VERSION "Infotainment_CAN_v1.0"

NS_ :

BS_:

BU_: VAL_SCENARIO_CTRL IVI CLU CGW TMU VOICE_ASSIST DATC HUD AMP

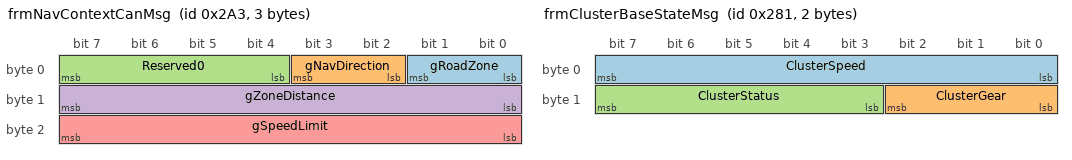
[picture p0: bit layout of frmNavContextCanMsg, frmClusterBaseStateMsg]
BO_ 675 frmNavContextCanMsg: 3 VAL_SCENARIO_CTRL
 SG_ gRoadZone : 0|2@1+ (1,0) [0|3] ""  IVI
 SG_ gNavDirection : 2|2@1+ (1,0) [0|3] ""  IVI
 SG_ Reserved0 : 4|4@1+ (1,0) [0|0] "" Vector__XXX
 SG_ gZoneDistance : 8|8@1+ (1,0) [0|255] "m"  IVI
 SG_ gSpeedLimit : 16|8@1+ (1,0) [0|255] "km/h"  IVI

BO_ 640 frmClusterWarningMsg: 1 IVI
 SG_ WarningTextCode : 0|8@1+ (1,0) [0|255] ""  CLU

BO_ 641 frmClusterBaseStateMsg: 2 IVI
 SG_ ClusterSpeed : 0|8@1+ (1,0) [0|255] "km/h"  CLU
 SG_ ClusterGear : 8|3@1+ (1,0) [0|7] ""  CLU
 SG_ ClusterStatus : 11|5@1+ (1,0) [0|31] ""  CLU

BO_ 642 frmNaviGuideStateMsg: 1 IVI
 SG_ GuideLaneState : 0|2@1+ (1,0) [0|3] ""  IVI
 SG_ GuideConfidence : 2|6@1+ (1,0) [0|63] ""  IVI

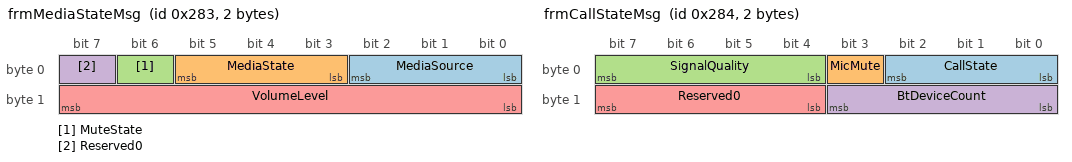
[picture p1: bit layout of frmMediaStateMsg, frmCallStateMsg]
BO_ 643 frmMediaStateMsg: 2 IVI
 SG_ MediaSource : 0|3@1+ (1,0) [0|7] ""  CLU
 SG_ MediaState : 3|3@1+ (1,0) [0|7] ""  CLU
 SG_ MuteState : 6|1@1+ (1,0) [0|1] ""  CLU
 SG_ Reserved0 : 7|1@1+ (1,0) [0|0] "" Vector__XXX
 SG_ VolumeLevel : 8|8@1+ (1,0) [0|100] "%"  CLU

BO_ 644 frmCallStateMsg: 2 IVI
 SG_ CallState : 0|3@1+ (1,0) [0|7] ""  CLU
 SG_ MicMute : 3|1@1+ (1,0) [0|1] ""  CLU
 SG_ SignalQuality : 4|4@1+ (1,0) [0|15] ""  CLU
 SG_ BtDeviceCount : 8|4@1+ (1,0) [0|15] ""  CLU
 SG_ Reserved0 : 12|4@1+ (1,0) [0|0] "" Vector__XXX

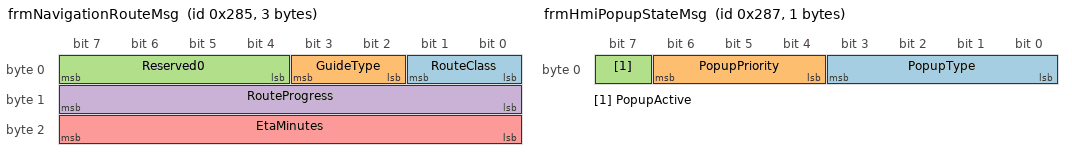
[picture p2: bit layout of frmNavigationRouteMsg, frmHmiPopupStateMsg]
BO_ 645 frmNavigationRouteMsg: 3 IVI
 SG_ RouteClass : 0|2@1+ (1,0) [0|3] ""  IVI
 SG_ GuideType : 2|2@1+ (1,0) [0|3] ""  IVI
 SG_ Reserved0 : 4|4@1+ (1,0) [0|0] "" Vector__XXX
 SG_ RouteProgress : 8|8@1+ (1,0) [0|100] "%"  IVI
 SG_ EtaMinutes : 16|8@1+ (1,0) [0|255] "min"  IVI

BO_ 646 frmClusterThemeMsg: 1 IVI
 SG_ ThemeMode : 0|3@1+ (1,0) [0|7] ""  CLU
 SG_ ClusterBrightness : 3|5@1+ (1,0) [0|31] ""  CLU

BO_ 647 frmHmiPopupStateMsg: 1 IVI
 SG_ PopupType : 0|4@1+ (1,0) [0|15] ""  CLU
 SG_ PopupPriority : 4|3@1+ (1,0) [0|7] ""  CLU
 SG_ PopupActive : 7|1@1+ (1,0) [0|1] ""  CLU

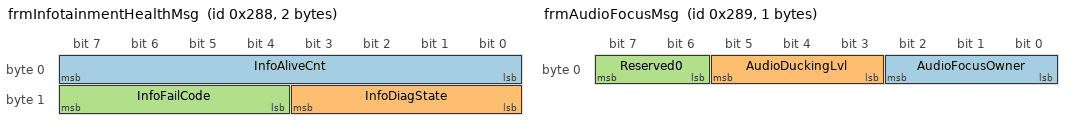
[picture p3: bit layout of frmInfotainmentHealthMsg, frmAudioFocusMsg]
BO_ 648 frmInfotainmentHealthMsg: 2 IVI
 SG_ InfoAliveCnt : 0|8@1+ (1,0) [0|255] ""  VAL_SCENARIO_CTRL,CGW
 SG_ InfoDiagState : 8|4@1+ (1,0) [0|15] ""  VAL_SCENARIO_CTRL,CGW
 SG_ InfoFailCode : 12|4@1+ (1,0) [0|15] ""  VAL_SCENARIO_CTRL,CGW

BO_ 649 frmAudioFocusMsg: 1 IVI
 SG_ AudioFocusOwner : 0|3@1+ (1,0) [0|7] ""  CLU
 SG_ AudioDuckingLvl : 3|3@1+ (1,0) [0|7] ""  CLU
 SG_ Reserved0 : 6|2@1+ (1,0) [0|0] "" Vector__XXX

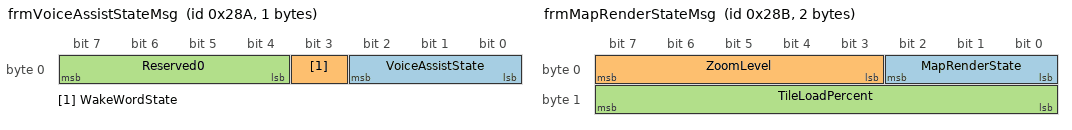
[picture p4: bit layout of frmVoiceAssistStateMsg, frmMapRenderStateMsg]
BO_ 650 frmVoiceAssistStateMsg: 1 VOICE_ASSIST
 SG_ VoiceAssistState : 0|3@1+ (1,0) [0|7] ""  CLU
 SG_ WakeWordState : 3|1@1+ (1,0) [0|1] ""  CLU
 SG_ Reserved0 : 4|4@1+ (1,0) [0|0] "" Vector__XXX

BO_ 651 frmMapRenderStateMsg: 2 IVI
 SG_ MapRenderState : 0|3@1+ (1,0) [0|7] ""  IVI
 SG_ ZoomLevel : 3|5@1+ (1,0) [0|31] ""  IVI
 SG_ TileLoadPercent : 8|8@1+ (1,0) [0|100] "%"  IVI

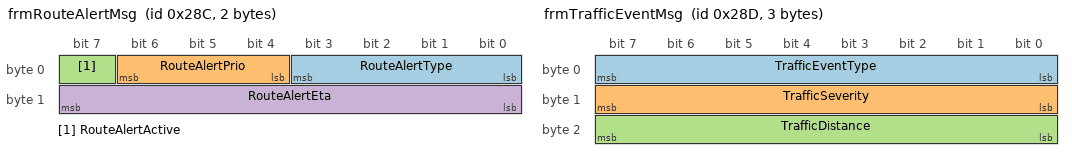
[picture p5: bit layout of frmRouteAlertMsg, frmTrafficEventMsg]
BO_ 652 frmRouteAlertMsg: 2 IVI
 SG_ RouteAlertType : 0|4@1+ (1,0) [0|15] ""  IVI
 SG_ RouteAlertPrio : 4|3@1+ (1,0) [0|7] ""  IVI
 SG_ RouteAlertActive : 7|1@1+ (1,0) [0|1] ""  IVI
 SG_ RouteAlertEta : 8|8@1+ (1,0) [0|255] "s"  IVI

BO_ 653 frmTrafficEventMsg: 3 IVI
 SG_ TrafficEventType : 0|8@1+ (1,0) [0|255] ""  IVI
 SG_ TrafficSeverity : 8|8@1+ (1,0) [0|255] ""  IVI
 SG_ TrafficDistance : 16|8@1+ (1,0) [0|255] "m"  IVI

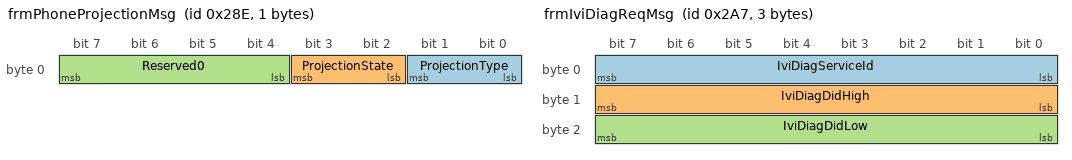
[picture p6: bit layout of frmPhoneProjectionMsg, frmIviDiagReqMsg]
BO_ 654 frmPhoneProjectionMsg: 1 IVI
 SG_ ProjectionType : 0|2@1+ (1,0) [0|3] ""  CLU
 SG_ ProjectionState : 2|2@1+ (1,0) [0|3] ""  CLU
 SG_ Reserved0 : 4|4@1+ (1,0) [0|0] "" Vector__XXX

BO_ 655 frmClusterNotifMsg: 2 IVI
 SG_ ClusterNotifType : 0|8@1+ (1,0) [0|255] ""  CLU
 SG_ ClusterNotifArg : 8|8@1+ (1,0) [0|255] ""  CLU

BO_ 679 frmIviDiagReqMsg: 3 VAL_SCENARIO_CTRL
 SG_ IviDiagServiceId : 0|8@1+ (1,0) [0|255] ""  IVI
 SG_ IviDiagDidHigh : 8|8@1+ (1,0) [0|255] ""  IVI
 SG_ IviDiagDidLow : 16|8@1+ (1,0) [0|255] ""  IVI

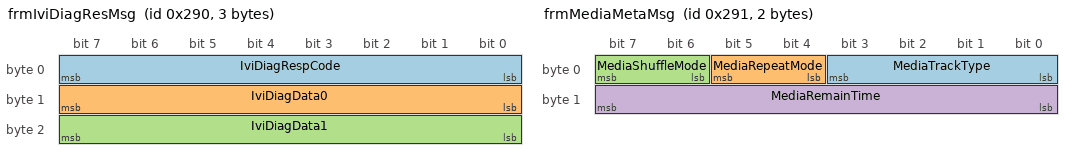
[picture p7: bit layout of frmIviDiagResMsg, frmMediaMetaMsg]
BO_ 656 frmIviDiagResMsg: 3 IVI
 SG_ IviDiagRespCode : 0|8@1+ (1,0) [0|255] ""  VAL_SCENARIO_CTRL
 SG_ IviDiagData0 : 8|8@1+ (1,0) [0|255] ""  VAL_SCENARIO_CTRL
 SG_ IviDiagData1 : 16|8@1+ (1,0) [0|255] ""  VAL_SCENARIO_CTRL

BO_ 657 frmMediaMetaMsg: 2 IVI
 SG_ MediaTrackType : 0|4@1+ (1,0) [0|15] ""  CLU
 SG_ MediaRepeatMode : 4|2@1+ (1,0) [0|3] ""  CLU
 SG_ MediaShuffleMode : 6|2@1+ (1,0) [0|3] ""  CLU
 SG_ MediaRemainTime : 8|8@1+ (1,0) [0|255] "s"  CLU

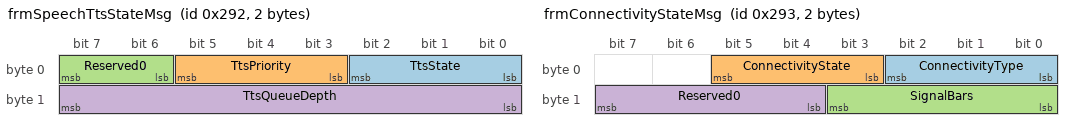
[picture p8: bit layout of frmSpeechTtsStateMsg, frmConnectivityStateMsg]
BO_ 658 frmSpeechTtsStateMsg: 2 VOICE_ASSIST
 SG_ TtsState : 0|3@1+ (1,0) [0|7] ""  CLU
 SG_ TtsPriority : 3|3@1+ (1,0) [0|7] ""  CLU
 SG_ Reserved0 : 6|2@1+ (1,0) [0|0] "" Vector__XXX
 SG_ TtsQueueDepth : 8|8@1+ (1,0) [0|255] ""  CLU

BO_ 659 frmConnectivityStateMsg: 2 IVI
 SG_ ConnectivityType : 0|3@1+ (1,0) [0|7] ""  IVI
 SG_ ConnectivityState : 3|3@1+ (1,0) [0|7] ""  IVI
 SG_ SignalBars : 8|4@1+ (1,0) [0|15] ""  IVI
 SG_ Reserved0 : 12|4@1+ (1,0) [0|0] "" Vector__XXX

BO_ 660 frmIviHealthDetailMsg: 2 IVI
 SG_ IviCpuLoad : 0|8@1+ (1,0) [0|100] "%"  VAL_SCENARIO_CTRL
 SG_ IviMemLoad : 8|8@1+ (1,0) [0|100] "%"  VAL_SCENARIO_CTRL

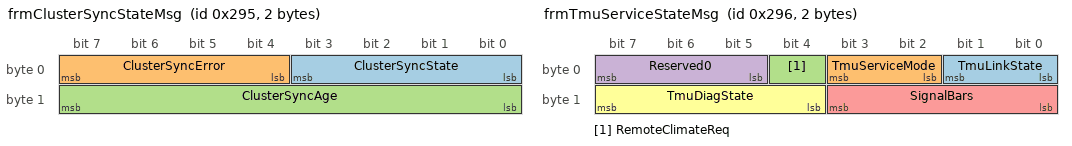
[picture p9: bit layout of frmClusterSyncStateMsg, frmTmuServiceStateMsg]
BO_ 661 frmClusterSyncStateMsg: 2 IVI
 SG_ ClusterSyncState : 0|4@1+ (1,0) [0|15] ""  CLU
 SG_ ClusterSyncError : 4|4@1+ (1,0) [0|15] ""  CLU
 SG_ ClusterSyncAge : 8|8@1+ (1,0) [0|255] "ms"  CLU

BO_ 662 frmTmuServiceStateMsg: 2 TMU
 SG_ TmuLinkState : 0|2@1+ (1,0) [0|3] ""  IVI,CLU,DATC,VAL_SCENARIO_CTRL
 SG_ TmuServiceMode : 2|2@1+ (1,0) [0|3] ""  IVI,CLU,DATC,VAL_SCENARIO_CTRL
 SG_ RemoteClimateReq : 4|1@1+ (1,0) [0|1] ""  DATC
 SG_ Reserved0 : 5|3@1+ (1,0) [0|0] "" Vector__XXX
 SG_ SignalBars : 8|4@1+ (1,0) [0|15] ""  IVI,CLU
 SG_ TmuDiagState : 12|4@1+ (1,0) [0|15] ""  IVI,CLU,VAL_SCENARIO_CTRL

BO_ 663 frmHudStateMsg: 3 HUD
 SG_ HudMode : 0|3@1+ (1,0) [0|7] ""  CLU,IVI,VAL_SCENARIO_CTRL
 SG_ Reserved0 : 3|5@1+ (1,0) [0|0] "" Vector__XXX
 SG_ HudWarningCode : 8|8@1+ (1,0) [0|255] ""  CLU,IVI,VAL_SCENARIO_CTRL
 SG_ HudGuideType : 16|4@1+ (1,0) [0|15] ""  CLU,IVI
 SG_ HudBrightness : 20|5@1+ (1,0) [0|31] ""  CLU,IVI

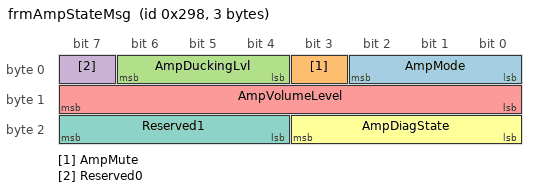
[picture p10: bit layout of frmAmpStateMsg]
BO_ 664 frmAmpStateMsg: 3 AMP
 SG_ AmpMode : 0|3@1+ (1,0) [0|7] ""  CLU,IVI,VOICE_ASSIST
 SG_ AmpMute : 3|1@1+ (1,0) [0|1] ""  CLU,IVI
 SG_ AmpDuckingLvl : 4|3@1+ (1,0) [0|7] ""  CLU,IVI,VOICE_ASSIST
 SG_ Reserved0 : 7|1@1+ (1,0) [0|0] "" Vector__XXX
 SG_ AmpVolumeLevel : 8|8@1+ (1,0) [0|100] "%"  CLU,IVI
 SG_ AmpDiagState : 16|4@1+ (1,0) [0|15] ""  CLU,IVI
 SG_ Reserved1 : 20|4@1+ (1,0) [0|0] "" Vector__XXX

CM_ BO_ 675 "Flow_003 navigation context input.";
CM_ BO_ 640 "Flow_008 cluster warning output.";
CM_ BO_ 641 "Infotainment baseline: cluster base display payload (speed/gear/status).";
CM_ BO_ 642 "Infotainment baseline: lane guidance state and confidence.";
CM_ BO_ 643 "Infotainment baseline: media source/state/mute/volume.";
CM_ BO_ 644 "Infotainment baseline: call state, mute, and signal quality.";
CM_ BO_ 645 "Infotainment baseline: route class/progress/ETA.";
CM_ BO_ 646 "Infotainment baseline: cluster theme and brightness.";
CM_ BO_ 647 "Infotainment baseline: popup type/priority/active flag.";
CM_ BO_ 648 "Infotainment health/diagnostic state.";
CM_ BO_ 649 "Comm_203: audio focus extension.";
CM_ BO_ 650 "Comm_203: voice assistant state extension.";
CM_ BO_ 651 "Comm_203: map render state extension.";
CM_ BO_ 652 "Comm_203: route alert extension.";
CM_ BO_ 653 "Comm_203: traffic event extension.";
CM_ BO_ 654 "Comm_203: phone projection extension.";
CM_ BO_ 655 "Comm_203: cluster notification extension.";
CM_ BO_ 679 "Comm_205: IVI diagnostic request.";
CM_ BO_ 656 "Comm_205: IVI diagnostic response.";
CM_ BO_ 657 "Comm_203: media metadata extension.";
CM_ BO_ 658 "Comm_203: speech TTS state extension.";
CM_ BO_ 659 "Comm_203: connectivity state extension.";
CM_ BO_ 660 "Comm_205: IVI health detail extension.";
CM_ BO_ 661 "Comm_203: cluster sync state extension.";
CM_ BO_ 662 "Telematics service/link state and remote climate request.";
CM_ BO_ 663 "HUD surface ECU state projected from CLU/IVI guidance and warning context.";
CM_ BO_ 664 "Amplifier surface ECU state derived from media focus, volume, and TTS ducking.";
BA_DEF_ BO_  "GenMsgCycleTime" INT 0 10000;
BA_DEF_DEF_  "GenMsgCycleTime" 0;
BA_ "GenMsgCycleTime" BO_ 675 100;
BA_ "GenMsgCycleTime" BO_ 640 50;
BA_ "GenMsgCycleTime" BO_ 641 50;
BA_ "GenMsgCycleTime" BO_ 642 100;
BA_ "GenMsgCycleTime" BO_ 643 100;
BA_ "GenMsgCycleTime" BO_ 644 100;
BA_ "GenMsgCycleTime" BO_ 645 100;
BA_ "GenMsgCycleTime" BO_ 646 50;
BA_ "GenMsgCycleTime" BO_ 647 50;
BA_ "GenMsgCycleTime" BO_ 648 100;
BA_ "GenMsgCycleTime" BO_ 649 50;
BA_ "GenMsgCycleTime" BO_ 650 50;
BA_ "GenMsgCycleTime" BO_ 651 50;
BA_ "GenMsgCycleTime" BO_ 652 50;
BA_ "GenMsgCycleTime" BO_ 653 100;
BA_ "GenMsgCycleTime" BO_ 654 50;
BA_ "GenMsgCycleTime" BO_ 655 50;
BA_ "GenMsgCycleTime" BO_ 657 50;
BA_ "GenMsgCycleTime" BO_ 658 50;
BA_ "GenMsgCycleTime" BO_ 659 100;
BA_ "GenMsgCycleTime" BO_ 660 100;
BA_ "GenMsgCycleTime" BO_ 661 50;
BA_ "GenMsgCycleTime" BO_ 662 100;
BA_ "GenMsgCycleTime" BO_ 663 50;
BA_ "GenMsgCycleTime" BO_ 664 50;
VAL_ 675 gRoadZone 0 "Normal" 1 "SchoolZone" 2 "Highway" 3 "Guide" ;
VAL_ 675 gNavDirection 0 "None" 1 "Left" 2 "Right" 3 "Other" ;
VAL_ 641 ClusterGear 0 "P" 1 "R" 2 "N" 3 "D" 4 "S" 5 "M" 6 "Reserved6" 7 "Reserved7" ;
VAL_ 641 ClusterStatus 0 "Normal" 1 "Navigation" 2 "Media" 3 "Call" 4 "Warning" 5 "Parking" 6 "Adas" 7 "Voice" 8 "Projection" 9 "Camera" 10 "Fault" ;
VAL_ 642 GuideLaneState 0 "None" 1 "Left" 2 "Right" 3 "Merge" ;
VAL_ 643 MediaSource 0 "None" 1 "Radio" 2 "Bluetooth" 3 "USB" 4 "Streaming" 5 "NaviVoice" 6 "Reserved6" 7 "Reserved7" ;
VAL_ 643 MediaState 0 "Stopped" 1 "Playing" 2 "Paused" 3 "Buffering" 4 "Error" 5 "Reserved5" 6 "Reserved6" 7 "Reserved7" ;
VAL_ 643 MuteState 0 "Unmuted" 1 "Muted" ;
VAL_ 644 CallState 0 "Idle" 1 "Ringing" 2 "Connected" 3 "OnHold" 4 "Ended" 5 "Reserved5" 6 "Reserved6" 7 "Reserved7" ;
VAL_ 644 MicMute 0 "Off" 1 "On" ;
VAL_ 645 RouteClass 0 "Local" 1 "Primary" 2 "Highway" 3 "Mixed" ;
VAL_ 645 GuideType 0 "None" 1 "Turn" 2 "LaneChange" 3 "Exit" ;
VAL_ 646 ThemeMode 0 "Default" 1 "Sport" 2 "Comfort" 3 "Eco" 4 "Night" 5 "Alert" 6 "Reserved6" 7 "Reserved7" ;
VAL_ 647 PopupType 0 "None" 1 "Call" 2 "Message" 3 "Navigation" 4 "Media" 5 "Warning" 6 "Parking" 7 "Adas" 8 "Climate" 9 "Voice" 10 "Projection" 11 "System" ;
VAL_ 647 PopupPriority 0 "None" 1 "Low" 2 "Medium" 3 "High" 4 "Critical" 5 "Emergency" ;
VAL_ 647 PopupActive 0 "Inactive" 1 "Active" ;
VAL_ 648 InfoDiagState 0 "Normal" 1 "Init" 2 "Warning" 3 "Degraded" 4 "Fault" 5 "Test" ;
VAL_ 649 AudioFocusOwner 0 "None" 1 "Media" 2 "Navigation" 3 "Call" 4 "VoiceAssist" 5 "Tts" 6 "Warning" 7 "Projection" ;
VAL_ 650 VoiceAssistState 0 "Idle" 1 "Listening" 2 "Thinking" 3 "Speaking" 4 "Error" ;
VAL_ 650 WakeWordState 0 "Off" 1 "On" ;
VAL_ 651 MapRenderState 0 "Idle" 1 "Loading" 2 "Rendering" 3 "Ready" 4 "Updating" 5 "Error" ;
VAL_ 652 RouteAlertType 0 "None" 1 "Turn" 2 "LaneChange" 3 "Exit" 4 "SpeedCamera" 5 "Traffic" 6 "Hazard" 7 "SchoolZone" 8 "Guide" ;
VAL_ 652 RouteAlertPrio 0 "None" 1 "Low" 2 "Medium" 3 "High" 4 "Critical" 5 "Emergency" ;
VAL_ 652 RouteAlertActive 0 "Inactive" 1 "Active" ;
VAL_ 653 TrafficEventType 0 "None" 1 "Accident" 2 "Congestion" 3 "RoadWork" 4 "Hazard" 5 "RoadClosure" 6 "Police" 7 "Weather" ;
VAL_ 653 TrafficSeverity 0 "None" 1 "Low" 2 "Medium" 3 "High" 4 "Critical" ;
VAL_ 654 ProjectionType 0 "None" 1 "CarPlay" 2 "AndroidAuto" 3 "Mirroring" ;
VAL_ 654 ProjectionState 0 "Disconnected" 1 "Connecting" 2 "Active" 3 "Error" ;
VAL_ 655 ClusterNotifType 0 "None" 1 "Message" 2 "Call" 3 "Navigation" 4 "Media" 5 "Warning" 6 "Service" 7 "Projection" 8 "Voice" ;
VAL_ 657 MediaTrackType 0 "None" 1 "Music" 2 "Podcast" 3 "Radio" 4 "Audiobook" 5 "Voice" 6 "Video" 7 "Ad" ;
VAL_ 657 MediaRepeatMode 0 "Off" 1 "One" 2 "All" 3 "Reserved3" ;
VAL_ 657 MediaShuffleMode 0 "Off" 1 "On" 2 "Smart" 3 "Reserved3" ;
VAL_ 658 TtsState 0 "Idle" 1 "Queued" 2 "Playing" 3 "Paused" 4 "Interrupted" 5 "Error" ;
VAL_ 658 TtsPriority 0 "None" 1 "Low" 2 "Medium" 3 "High" 4 "Critical" 5 "Emergency" ;
VAL_ 659 ConnectivityType 0 "None" 1 "Cellular" 2 "WiFi" 3 "Bluetooth" 4 "Ethernet" 5 "V2X" 6 "USB" 7 "Other" ;
VAL_ 659 ConnectivityState 0 "Disconnected" 1 "Searching" 2 "Connecting" 3 "Connected" 4 "Limited" 5 "Roaming" 6 "Error" 7 "Off" ;
VAL_ 661 ClusterSyncState 0 "Idle" 1 "Syncing" 2 "Synced" 3 "Stale" 4 "Error" ;
VAL_ 661 ClusterSyncError 0 "None" 1 "Timeout" 2 "Crc" 3 "Version" 4 "Sequence" 5 "Transport" 6 "DataRange" 7 "Unknown" ;
VAL_ 662 TmuLinkState 0 "Offline" 1 "Limited" 2 "Online" 3 "Fault" ;
VAL_ 662 TmuServiceMode 0 "Off" 1 "Standby" 2 "Active" 3 "Emergency" ;
VAL_ 662 RemoteClimateReq 0 "NoReq" 1 "Request" ;
VAL_ 662 TmuDiagState 0 "Normal" 1 "Init" 2 "Warning" 3 "Degraded" 4 "Fault" 5 "Test" ;
VAL_ 663 HudMode 0 "Off" 1 "Basic" 2 "Navigation" 3 "Adas" 4 "Warning" 5 "Full" ;
VAL_ 663 HudGuideType 0 "None" 1 "Turn" 2 "LaneChange" 3 "Exit" 4 "Merge" 5 "Warning" ;
VAL_ 664 AmpMode 0 "Off" 1 "Standby" 2 "Active" 3 "Muted" 4 "Fault" ;
VAL_ 664 AmpMute 0 "Off" 1 "On" ;
VAL_ 664 AmpDiagState 0 "Normal" 1 "Init" 2 "Warning" 3 "Degraded" 4 "Fault" 5 "Test" ;
